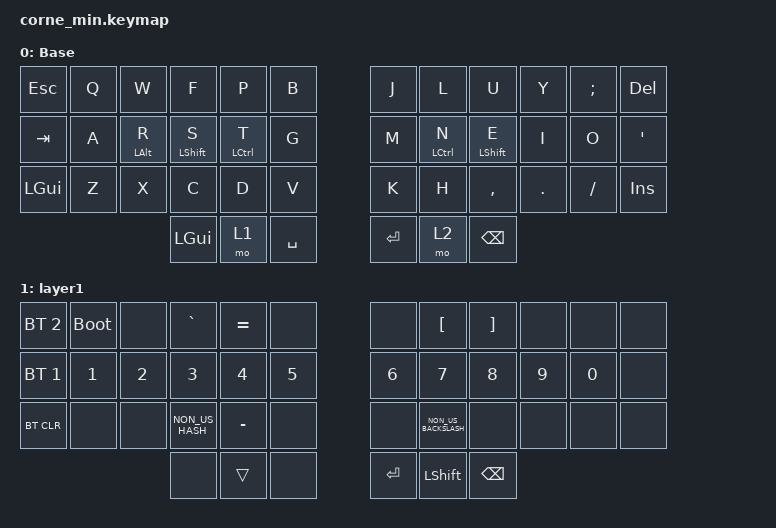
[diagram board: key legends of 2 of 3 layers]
/*
 * Copyright (c) 2020 The ZMK Contributors
 *
 * SPDX-License-Identifier: MIT
 */

#include <behaviors.dtsi>
#include <dt-bindings/zmk/keys.h>
#include <dt-bindings/zmk/bt.h>
#include <dt-bindings/zmk/behaviors.h>

/ {
            behaviors {
        mt: mod_tap {
            compatible = "zmk,behavior-hold-tap";
            #binding-cells = <2>;
            flavor = "hold-preferred";
            tapping-term-ms = <750>;
            bindings = <&kp>, <&kp>;
            display-name = "Mod-Tap";
        };
                hml: home_row_mod_left {
            compatible = "zmk,behavior-hold-tap";
            #binding-cells = <2>;
            flavor = "balanced";
            require-prior-idle-ms = <150>;
            tapping-term-ms = <280>;
            quick-tap-ms = <175>;
            bindings = <&kp>, <&kp>;
            hold-trigger-key-positions = < 3 4 5 >; 
            hold-trigger-on-release;
        };
        hmr: home_row_mod_right {
            compatible = "zmk,behavior-hold-tap";
            #binding-cells = <2>;
            flavor = "balanced";
            require-prior-idle-ms = <150>;
            tapping-term-ms = <280>;
            quick-tap-ms = <175>;
            bindings = <&kp>, <&kp>;
            hold-trigger-key-positions = <8 9>;
            hold-trigger-on-release;
        };
    };
        keymap {
                compatible = "zmk,keymap";

                default_layer {
                            display-name = "Base";
// -----------------------------------------------------------------------------------------
// | ESC |  Q  |  W  |  F  |  P  |  B  |   |  J  |  L   |  U  |  Y  |  ;  | DEL |
// | TAB |  A  |  R  |  S  |  T  |  G  |   |  H  |  N   |  E  |  I  |  O  |  '   |
// | GUI |  Z  |  X  |  C  |  D  |  V  |   |  K  |  M   |  ,  |  .  |  /  | INS  |
//                    | GUI | LWR | SPC |   | ENT | RSE  | BACKSPACE |
        bindings = <
        &kp ESC &kp Q &kp W &kp F &kp P &kp B &kp J &kp L &kp U &kp Y &kp SEMI &kp DEL
        &kp TAB &kp A &hml LALT R &hml LSHFT S &hml LCTRL T &kp G &kp M &hmr LCTRL N &hmr LSHFT E &kp I &kp O &kp APOS
        &kp LGUI &kp Z &kp X &kp C &kp D &kp V &kp K &kp H &kp COMMA &kp DOT &kp SLASH &kp INS
        &kp LGUI &mo 1 &kp SPACE &kp ENTER &mo 2 &kp BACKSPACE
        >;
        };
// -----------------------------------------------------------------------------------------
// | BT_2  | boot|     |  `  |  =  |     |   |     |  [   |  ]  |     |     |     |
// | BT_1  |  1  |  2  |  3  |  4  |  5  |   |  6  |  7   |  8  |  9  |  0  |     |
// |BT_CLR |     |     |  #  |  –  |     |   |     |  \   |     |     |     |     |
//                     |     |     |     |   |  ↑  | SHFT |  ⌫  |
                layer1 {
          bindings = <
          &bt BT_SEL 2 &bootloader &none &kp GRAVE &kp EQUAL &none &none &kp LEFT_BRACKET &kp RIGHT_BRACKET &none &none &none
          &bt BT_SEL 1 &kp N1 &kp N2 &kp N3 &kp N4 &kp N5 &kp N6 &kp N7 &kp N8 &kp N9 &kp N0 &none 
          &bt BT_CLR &none &none &kp NON_US_HASH &kp MINUS &none &none &kp NON_US_BACKSLASH &none &none &none &none
          &none &trans &none &kp ENTER &kp LEFT_SHIFT &kp BACKSPACE
          >;
                };

// -----------------------------------------------------------------------------------------
// | VolUp | F1  | F2  | F3  | F4  | F5  |   | F6  | F7   | F8  | F9  | F10 |  bootloader   |
// | VolDn |     |     |     |     |     |   |     |  ←   |  ↑  |  ↓  |  →  |     |
// | Mute  |     |     | Prev| Play| Next|   |     | Home | PgUp| PgDwn | END |  Ins |
//                    |     |     |     |   |     |      |     |
                layer2 {
          bindings = <
          &kp C_VOLUME_UP &kp F1 &kp F2 &kp F3 &kp F4 &kp F5 &kp F6 &kp F7 &kp F8 &kp F9 &kp F10 &bootloader
          &kp C_VOLUME_DOWN &none &none &none &none &none &none &kp LEFT &kp UP &kp DOWN &kp RIGHT &none
          &kp C_MUTE &none &none &kp C_PREVIOUS &kp C_PLAY_PAUSE &kp C_NEXT &none &none &kp HOME &kp PAGE_UP &kp PAGE_DOWN &kp END &none &kp INSERT
          &none &none &none &none &trans &none
          >;
                };

                extra1 {
                        display-name = "Extra-1";
                        status = "reserved";
                };

                extra2 {
                        display-name = "Extra-2";
                        status = "reserved";
                };

                extra3 {
                        display-name = "Extra-3";
                        status = "reserved";
                };
        };
};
